AUTOSAR XML (schema 4-2-1)
package /RootP_ASWC_DISPATCH_CORE0_SWPQM
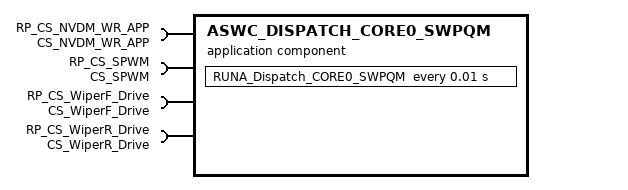
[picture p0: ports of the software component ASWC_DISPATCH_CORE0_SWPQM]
  application sw component type ASWC_DISPATCH_CORE0_SWPQM
    4 x require port:
      RP_CS_NVDM_WR_APP: client-com-spec=NvDM_WrApp_Block, required-interface=CS_NVDM_WR_APP
      RP_CS_SPWM: client-com-spec=Set, required-interface=CS_SPWM
      RP_CS_WiperF_Drive: client-com-spec=OP_SET, required-interface=CS_WiperF_Drive
      RP_CS_WiperR_Drive: client-com-spec=OP_SET, required-interface=CS_WiperR_Drive
    behavior IB_ASWC_DISPATCH_CORE0_SWPQM: handle-termination-and-restart=NO-SUPPORT
      timing event RUNA_Dispatch_Cyclic: start-on-event=RUNA_Dispatch_CORE0_SWPQM, period=0.01
      runnable RUNA_Dispatch_CORE0_SWPQM: can-be-invoked-concurrently=true
        4 x sync call, all with timeout=0.0:
          scp_NVDM_WR_APP_NvDM_WrApp_Block: operation=RP_CS_NVDM_WR_APP.NvDM_WrApp_Block
          scp_SPWM_Set: operation=RP_CS_SPWM.Set
          scp_WiperF_Drive_OP_SET: operation=RP_CS_WiperF_Drive.OP_SET
          scp_WiperR_Drive_OP_SET: operation=RP_CS_WiperR_Drive.OP_SET
  swc implementation ASWC_DISPATCH_CORE0_SWPQM_Impl: programming-language=C, sw-version=1.0.0, vendor-id=0, behavior=IB_ASWC_DISPATCH_CORE0_SWPQM
    code-descriptors:
      code SRC: artifact-descriptors=autosar-engineering-object={short-label=EngObject, category=SWSRC}
    resource consumption Resources
      memory section CODE: sw-addrmethod=CODE_ASWC_DISPATCH_CORE0_SWPQM
  sw addr method CODE_ASWC_DISPATCH_CORE0_SWPQM: memory-allocation-keyword-policy=ADDR-METHOD-SHORT-NAME-AND-ALIGNMENT, section-type=CODE
